VERSION ""

NS_ :

BS_:

BU_: CH DIPF DIPR ETH FC HVI HVS PARTY SDCV VEH VIRT

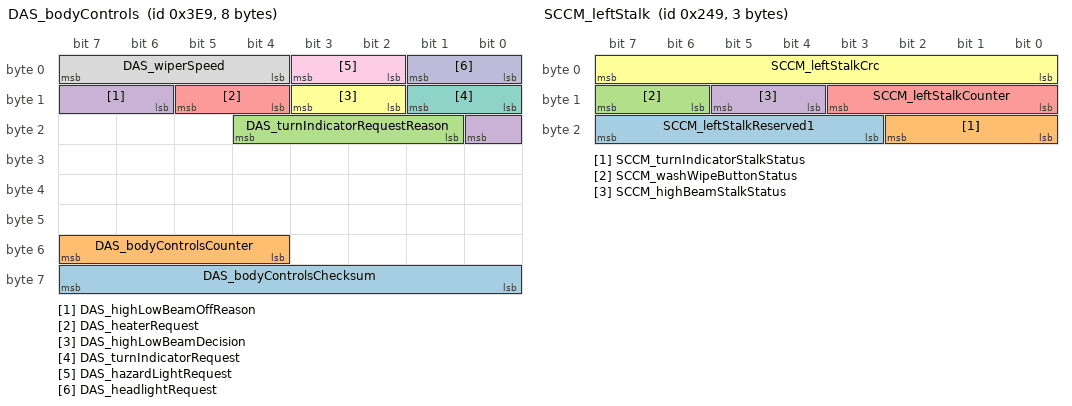
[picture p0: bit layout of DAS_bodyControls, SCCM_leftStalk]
BO_ 1001 DAS_bodyControls: 8 VEH
 SG_ DAS_bodyControlsChecksum : 56|8@1+ (1,0) [0|255] ""  aps
 SG_ DAS_bodyControlsCounter : 52|4@1+ (1,0) [0|15] ""  aps
 SG_ DAS_turnIndicatorRequestReason : 17|4@1+ (1,0) [0|8] ""  aps
 SG_ DAS_highLowBeamOffReason : 14|3@1+ (1,0) [0|5] ""  aps
 SG_ DAS_heaterRequest : 12|2@1+ (1,0) [0|2] ""  aps
 SG_ DAS_highLowBeamDecision : 10|2@1+ (1,0) [0|3] ""  aps
 SG_ DAS_turnIndicatorRequest : 8|2@1+ (1,0) [0|3] ""  aps
 SG_ DAS_wiperSpeed : 4|4@1+ (1,0) [0|15] ""  aps
 SG_ DAS_hazardLightRequest : 2|2@1+ (1,0) [0|3] ""  aps
 SG_ DAS_headlightRequest : 0|2@1+ (1,0) [0|3] ""  aps

BO_ 585 SCCM_leftStalk: 3 VEH
 SG_ SCCM_leftStalkReserved1 : 19|5@1+ (1,0) [0|31] ""  X
 SG_ SCCM_turnIndicatorStalkStatus : 16|3@1+ (1,0) [0|5] ""  das
 SG_ SCCM_washWipeButtonStatus : 14|2@1+ (1,0) [0|3] ""  das
 SG_ SCCM_highBeamStalkStatus : 12|2@1+ (1,0) [0|3] ""  das
 SG_ SCCM_leftStalkCounter : 8|4@1+ (1,0) [0|15] ""  X
 SG_ SCCM_leftStalkCrc : 0|8@1+ (1,0) [0|255] ""  X

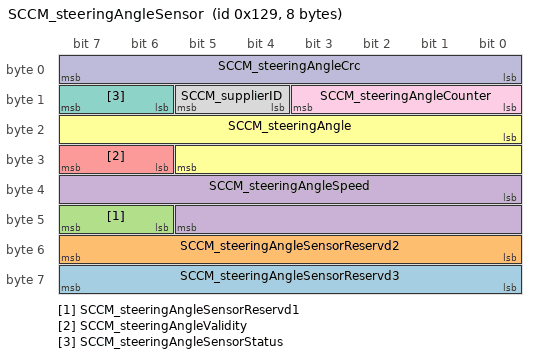
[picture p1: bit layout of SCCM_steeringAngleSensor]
BO_ 297 SCCM_steeringAngleSensor: 8 VEH
 SG_ SCCM_steeringAngleSensorReservd3 : 56|8@1+ (1,0) [0|255] ""  X
 SG_ SCCM_steeringAngleSensorReservd2 : 48|8@1+ (1,0) [0|255] ""  X
 SG_ SCCM_steeringAngleSensorReservd1 : 46|2@1+ (1,0) [0|3] ""  X
 SG_ SCCM_steeringAngleSpeed : 32|14@1+ (0.5,-4096) [-4096|4095.5] "deg/s"  das
 SG_ SCCM_steeringAngleValidity : 30|2@1+ (1,0) [0|3] ""  gtw
 SG_ SCCM_steeringAngle : 16|14@1+ (0.1,-819.2) [-819.2|819] "deg"  aps
 SG_ SCCM_steeringAngleSensorStatus : 14|2@1+ (1,0) [0|3] ""  aps
 SG_ SCCM_supplierID : 12|2@1+ (1,0) [0|3] ""  gtw
 SG_ SCCM_steeringAngleCounter : 8|4@1+ (1,0) [0|15] ""  gtw
 SG_ SCCM_steeringAngleCrc : 0|8@1+ (1,0) [0|255] ""  gtw

VAL_ 1001 DAS_turnIndicatorRequestReason 8 "DAS_ACTIVE_COMMANDED_LANE_CHANGE" 4 "DAS_CANCEL_LANE_CHANGE" 6 "DAS_ACTIVE_MERGE" 2 "DAS_ACTIVE_SPEED_LANE_CHANGE" 5 "DAS_CANCEL_FORK" 0 "DAS_NONE" 3 "DAS_ACTIVE_FORK" 7 "DAS_CANCEL_MERGE" 1 "DAS_ACTIVE_NAV_LANE_CHANGE" ;
VAL_ 1001 DAS_highLowBeamOffReason 0 "HIGH_BEAM_ON" 3 "HIGH_BEAM_OFF_REASON_AMBIENT_LIGHT" 1 "HIGH_BEAM_OFF_REASON_MOVING_VISION_TARGET" 2 "HIGH_BEAM_OFF_REASON_MOVING_RADAR_TARGET" 4 "HIGH_BEAM_OFF_REASON_HEAD_LIGHT" 5 "HIGH_BEAM_OFF_REASON_SNA" ;
VAL_ 1001 DAS_heaterRequest 0 "DAS_HEATER_SNA" 2 "DAS_HEATER_ON" 1 "DAS_HEATER_OFF" ;
VAL_ 1001 DAS_highLowBeamDecision 2 "DAS_HIGH_BEAM_ON" 1 "DAS_HIGH_BEAM_OFF" 3 "DAS_HIGH_BEAM_SNA" 0 "DAS_HIGH_BEAM_UNDECIDED" ;
VAL_ 1001 DAS_turnIndicatorRequest 0 "DAS_TURN_INDICATOR_NONE" 2 "DAS_TURN_INDICATOR_RIGHT" 3 "DAS_TURN_INDICATOR_CANCEL" 1 "DAS_TURN_INDICATOR_LEFT" ;
VAL_ 1001 DAS_wiperSpeed 3 "DAS_WIPER_SPEED_3" 12 "DAS_WIPER_SPEED_12" 8 "DAS_WIPER_SPEED_8" 14 "DAS_WIPER_SPEED_14" 5 "DAS_WIPER_SPEED_5" 13 "DAS_WIPER_SPEED_13" 2 "DAS_WIPER_SPEED_2" 0 "DAS_WIPER_SPEED_OFF" 4 "DAS_WIPER_SPEED_4" 1 "DAS_WIPER_SPEED_1" 15 "DAS_WIPER_SPEED_INVALID" 10 "DAS_WIPER_SPEED_10" 11 "DAS_WIPER_SPEED_11" 7 "DAS_WIPER_SPEED_7" 9 "DAS_WIPER_SPEED_9" 6 "DAS_WIPER_SPEED_6" ;
VAL_ 1001 DAS_hazardLightRequest 3 "DAS_REQUEST_HAZARDS_SNA" 2 "DAS_REQUEST_HAZARDS_UNUSED" 0 "DAS_REQUEST_HAZARDS_OFF" 1 "DAS_REQUEST_HAZARDS_ON" ;
VAL_ 1001 DAS_headlightRequest 3 "DAS_HEADLIGHT_REQUEST_INVALID" 1 "DAS_HEADLIGHT_REQUEST_ON" 0 "DAS_HEADLIGHT_REQUEST_OFF" ;
VAL_ 585 SCCM_turnIndicatorStalkStatus 3 "DOWN_1" 5 "SNA" 0 "IDLE" 1 "UP_1" 4 "DOWN_2" 2 "UP_2" ;
VAL_ 585 SCCM_washWipeButtonStatus 3 "SNA" 0 "NOT_PRESSED" 2 "2ND_DETENT" 1 "1ST_DETENT" ;
VAL_ 585 SCCM_highBeamStalkStatus 3 "SNA" 0 "IDLE" 1 "PULL" 2 "PUSH" ;
VAL_ 297 SCCM_steeringAngleValidity 3 "SNA" 2 "INIT" 0 "INVALID" 1 "VALID" ;
VAL_ 297 SCCM_steeringAngleSensorStatus 0 "OK" 1 "INIT" 2 "ERROR" 3 "ERROR_INIT" ;
